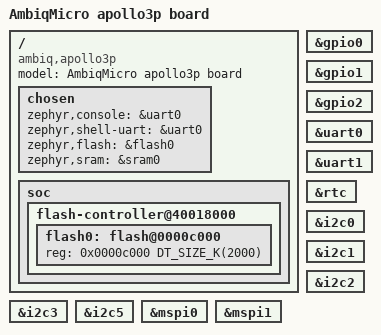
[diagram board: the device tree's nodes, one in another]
/*
 * Copyright (c) 2020 CKT
 *
 * SPDX-License-Identifier: Apache-2.0
 */
 
/dts-v1/;
#include <ambiq/apollo3p.dtsi>


/ {
	model = "AmbiqMicro apollo3p board";
	compatible = "ambiq,apollo3p";
	
	chosen {
		zephyr,console = &uart0;
		zephyr,shell-uart = &uart0;
		zephyr,flash = &flash0;
		zephyr,sram = &sram0;
		/*zephyr,ccm = &ccm0;*/
	};
	
	soc {
		flash-controller@40018000 {
			flash0: flash@0000c000 {
				reg = <0x0000c000 DT_SIZE_K(2000)>;
			};
		};
	};
};

&gpio0 {
    status = "okay";
};

&gpio1 {
    status = "okay";
};

&gpio2 {
    status = "okay";
};

&uart0 {
    status = "okay";
};

&uart1 {
    status = "okay";
};

&rtc {
    status = "okay";
};

&i2c0 {
    status = "okay";
};

&i2c1 {
    status = "okay";
};

&i2c2 {
    status = "okay";
};

&i2c3 {
    status = "okay";
};

&i2c5 {
    status = "okay";
};

&mspi0 {
    status = "okay";
};

&mspi1 {
    status = "okay";
};


